VERSION ""

NS_ :

BS_:

BU_: BMS Third_Party_Device

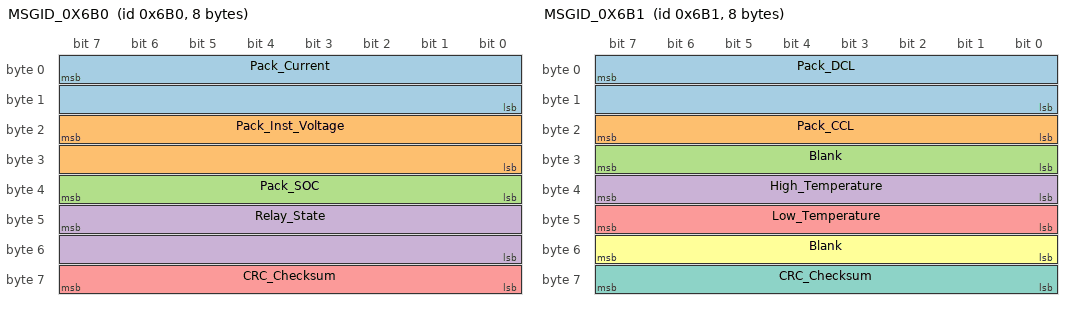
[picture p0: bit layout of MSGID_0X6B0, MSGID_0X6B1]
BO_ 1712 MSGID_0X6B0: 8 BMS
 SG_ Pack_Current : 7|16@0+ (0.1,0) [0|0] "Amps"  Third_Party_Device
 SG_ Pack_Inst_Voltage : 23|16@0+ (0.1,0) [0|0] "Volts"  Third_Party_Device
 SG_ Pack_SOC : 39|8@0+ (0.5,0) [0|0] "Percent"  Third_Party_Device
 SG_ Relay_State : 47|16@0+ (1.0,0) [0|0] ""  Third_Party_Device
 SG_ CRC_Checksum : 63|8@0+ (1.0,1720) [0|0] ""  Third_Party_Device

BO_ 1713 MSGID_0X6B1: 8 BMS
 SG_ Pack_DCL : 7|16@0+ (1.0,0) [0|0] "Amps"  Third_Party_Device
 SG_ Pack_CCL : 23|8@0+ (1.0,0) [0|0] "Amps"  Third_Party_Device
 SG_ Blank : 31|8@0+ (1.0,0) [0|0] ""  Third_Party_Device
 SG_ High_Temperature : 39|8@0+ (1.0,0) [0|0] "Celsius"  Third_Party_Device
 SG_ Low_Temperature : 47|8@0+ (1.0,0) [0|0] "Celsius"  Third_Party_Device
 SG_ Blank : 55|8@0+ (1.0,0) [0|0] ""  Third_Party_Device
 SG_ CRC_Checksum : 63|8@0+ (1.0,1721) [0|0] ""  Third_Party_Device

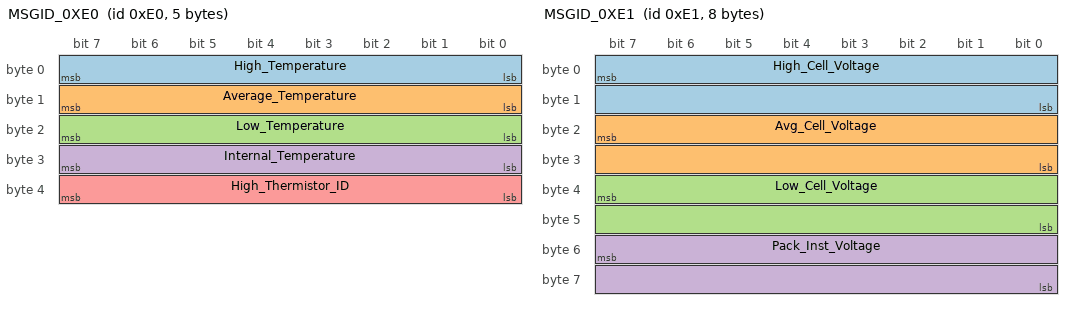
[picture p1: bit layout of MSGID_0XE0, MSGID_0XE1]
BO_ 224 MSGID_0XE0: 5 BMS
 SG_ High_Temperature : 7|8@0+ (1.0,0) [0|0] "Celsius"  Third_Party_Device
 SG_ Average_Temperature : 15|8@0+ (1.0,0) [0|0] "Celsius"  Third_Party_Device
 SG_ Low_Temperature : 23|8@0+ (1.0,0) [0|0] "Celsius"  Third_Party_Device
 SG_ Internal_Temperature : 31|8@0+ (1.0,0) [0|0] "Celsius"  Third_Party_Device
 SG_ High_Thermistor_ID : 39|8@0+ (1.0,0) [0|0] "ID"  Third_Party_Device

BO_ 225 MSGID_0XE1: 8 BMS
 SG_ High_Cell_Voltage : 7|16@0+ (1.0E-4,0) [0|0] "Volts"  Third_Party_Device
 SG_ Avg_Cell_Voltage : 23|16@0+ (1.0E-4,0) [0|0] "Volts"  Third_Party_Device
 SG_ Low_Cell_Voltage : 39|16@0+ (1.0E-4,0) [0|0] "Volts"  Third_Party_Device
 SG_ Pack_Inst_Voltage : 55|16@0+ (0.1,0) [0|0] "Volts"  Third_Party_Device

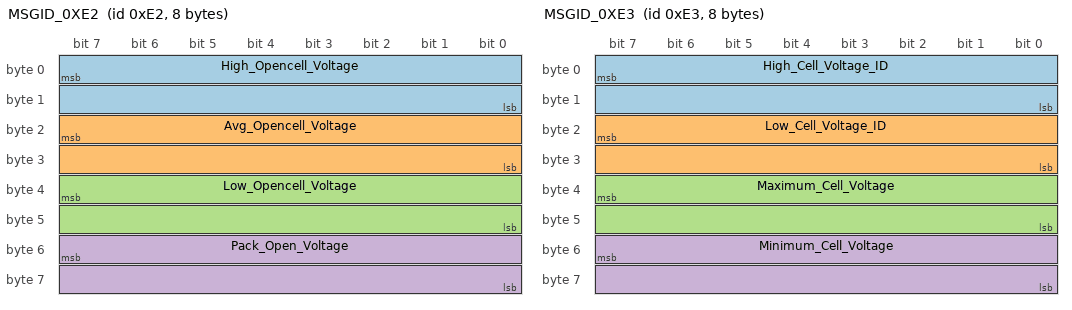
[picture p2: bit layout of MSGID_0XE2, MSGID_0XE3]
BO_ 226 MSGID_0XE2: 8 BMS
 SG_ High_Opencell_Voltage : 7|16@0+ (1.0E-4,0) [0|0] "Volts"  Third_Party_Device
 SG_ Avg_Opencell_Voltage : 23|16@0+ (1.0E-4,0) [0|0] "Volts"  Third_Party_Device
 SG_ Low_Opencell_Voltage : 39|16@0+ (1.0E-4,0) [0|0] "Volts"  Third_Party_Device
 SG_ Pack_Open_Voltage : 55|16@0+ (0.1,0) [0|0] "Volts"  Third_Party_Device

BO_ 227 MSGID_0XE3: 8 BMS
 SG_ High_Cell_Voltage_ID : 7|16@0+ (1.0,0) [0|0] "ID"  Third_Party_Device
 SG_ Low_Cell_Voltage_ID : 23|16@0+ (1.0,0) [0|0] "ID"  Third_Party_Device
 SG_ Maximum_Cell_Voltage : 39|16@0+ (1.0E-4,0) [0|0] "Volts"  Third_Party_Device
 SG_ Minimum_Cell_Voltage : 55|16@0+ (1.0E-4,0) [0|0] "Volts"  Third_Party_Device

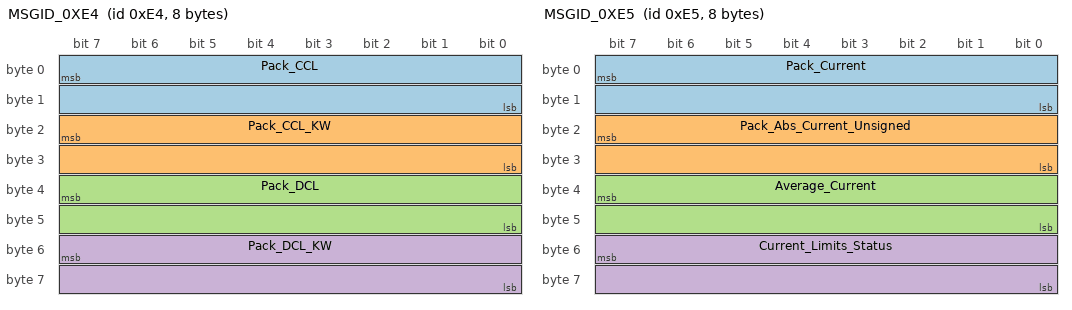
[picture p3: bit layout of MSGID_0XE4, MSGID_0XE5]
BO_ 228 MSGID_0XE4: 8 BMS
 SG_ Pack_CCL : 7|16@0+ (1.0,0) [0|0] "Amps"  Third_Party_Device
 SG_ Pack_CCL_KW : 23|16@0+ (0.1,0) [0|0] "kW"  Third_Party_Device
 SG_ Pack_DCL : 39|16@0+ (1.0,0) [0|0] "Amps"  Third_Party_Device
 SG_ Pack_DCL_KW : 55|16@0+ (0.1,0) [0|0] "kW"  Third_Party_Device

BO_ 229 MSGID_0XE5: 8 BMS
 SG_ Pack_Current : 7|16@0+ (0.1,0) [0|0] "Amps"  Third_Party_Device
 SG_ Pack_Abs_Current_Unsigned : 23|16@0+ (0.1,0) [0|0] "Amps"  Third_Party_Device
 SG_ Average_Current : 39|16@0+ (0.1,0) [0|0] "Amps"  Third_Party_Device
 SG_ Current_Limits_Status : 55|16@0+ (1.0,0) [0|0] ""  Third_Party_Device

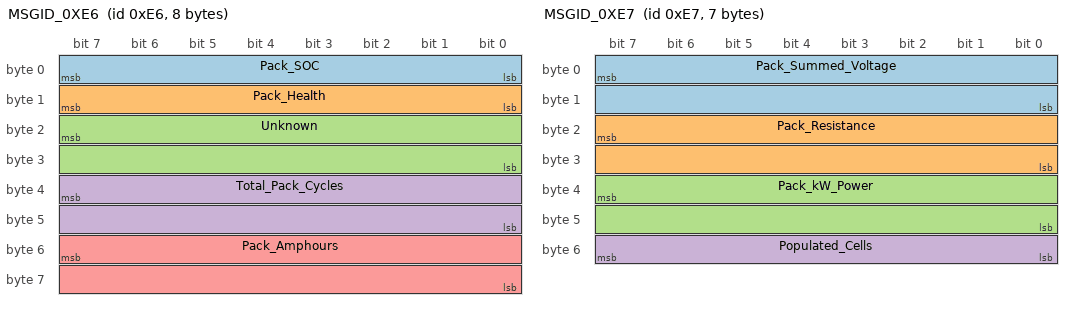
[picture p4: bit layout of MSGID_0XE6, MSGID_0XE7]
BO_ 230 MSGID_0XE6: 8 BMS
 SG_ Pack_SOC : 7|8@0+ (0.5,0) [0|0] "Percent"  Third_Party_Device
 SG_ Pack_Health : 15|8@0+ (1.0,0) [0|0] "Percent"  Third_Party_Device
 SG_ Unknown : 23|16@0+ (1.0,0) [0|0] ""  Third_Party_Device
 SG_ Total_Pack_Cycles : 39|16@0+ (1.0,0) [0|0] "Num"  Third_Party_Device
 SG_ Pack_Amphours : 55|16@0+ (0.1,0) [0|0] "Amphours"  Third_Party_Device

BO_ 231 MSGID_0XE7: 7 BMS
 SG_ Pack_Summed_Voltage : 7|16@0+ (0.01,0) [0|0] "Volts"  Third_Party_Device
 SG_ Pack_Resistance : 23|16@0+ (0.001,0) [0|0] "Ohms"  Third_Party_Device
 SG_ Pack_kW_Power : 39|16@0+ (0.1,0) [0|0] "kW"  Third_Party_Device
 SG_ Populated_Cells : 55|8@0+ (1.0,0) [0|0] "Num"  Third_Party_Device

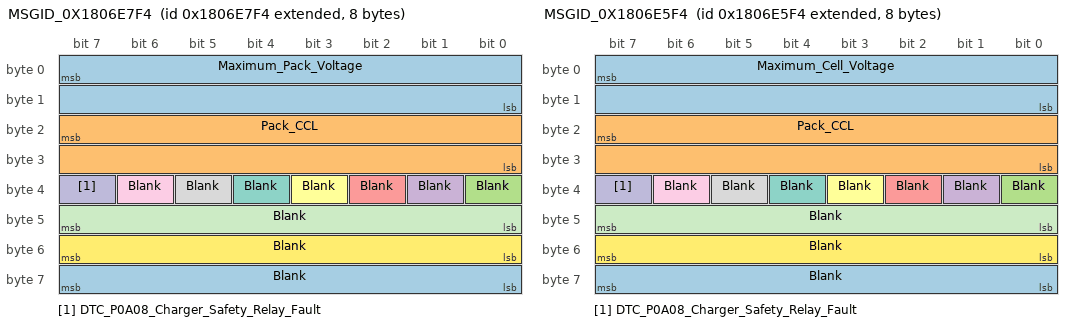
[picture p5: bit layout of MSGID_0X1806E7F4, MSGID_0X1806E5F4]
BO_ 2550589428 MSGID_0X1806E7F4: 8 BMS
 SG_ Maximum_Pack_Voltage : 7|16@0+ (0.1,0) [0|0] "Volts"  Third_Party_Device
 SG_ Pack_CCL : 23|16@0+ (0.1,0) [0|0] "Amps"  Third_Party_Device
 SG_ Blank : 32|1@1+ (1.0,0) [0|1] ""  Third_Party_Device
 SG_ Blank : 33|1@1+ (1.0,0) [0|1] ""  Third_Party_Device
 SG_ Blank : 34|1@1+ (1.0,0) [0|1] ""  Third_Party_Device
 SG_ Blank : 35|1@1+ (1.0,0) [0|1] ""  Third_Party_Device
 SG_ Blank : 36|1@1+ (1.0,0) [0|1] ""  Third_Party_Device
 SG_ Blank : 37|1@1+ (1.0,0) [0|1] ""  Third_Party_Device
 SG_ Blank : 38|1@1+ (1.0,0) [0|1] ""  Third_Party_Device
 SG_ DTC_P0A08_Charger_Safety_Relay_Fault : 39|1@1+ (1.0,0) [0|1] ""  Third_Party_Device
 SG_ Blank : 47|8@0+ (0.1,0) [0|0] ""  Third_Party_Device
 SG_ Blank : 55|8@0+ (1.0,0) [0|0] ""  Third_Party_Device
 SG_ Blank : 63|8@0+ (1.0,0) [0|0] ""  Third_Party_Device

BO_ 2550588916 MSGID_0X1806E5F4: 8 BMS
 SG_ Maximum_Cell_Voltage : 7|16@0+ (7.142857142857144E-4,0) [0|0] "Volts"  Third_Party_Device
 SG_ Pack_CCL : 23|16@0+ (0.1,0) [0|0] "Amps"  Third_Party_Device
 SG_ Blank : 32|1@1+ (1.0,0) [0|1] ""  Third_Party_Device
 SG_ Blank : 33|1@1+ (1.0,0) [0|1] ""  Third_Party_Device
 SG_ Blank : 34|1@1+ (1.0,0) [0|1] ""  Third_Party_Device
 SG_ Blank : 35|1@1+ (1.0,0) [0|1] ""  Third_Party_Device
 SG_ Blank : 36|1@1+ (1.0,0) [0|1] ""  Third_Party_Device
 SG_ Blank : 37|1@1+ (1.0,0) [0|1] ""  Third_Party_Device
 SG_ Blank : 38|1@1+ (1.0,0) [0|1] ""  Third_Party_Device
 SG_ DTC_P0A08_Charger_Safety_Relay_Fault : 39|1@1+ (1.0,0) [0|1] ""  Third_Party_Device
 SG_ Blank : 47|8@0+ (0.1,0) [0|0] ""  Third_Party_Device
 SG_ Blank : 55|8@0+ (1.0,0) [0|0] ""  Third_Party_Device
 SG_ Blank : 63|8@0+ (1.0,0) [0|0] ""  Third_Party_Device

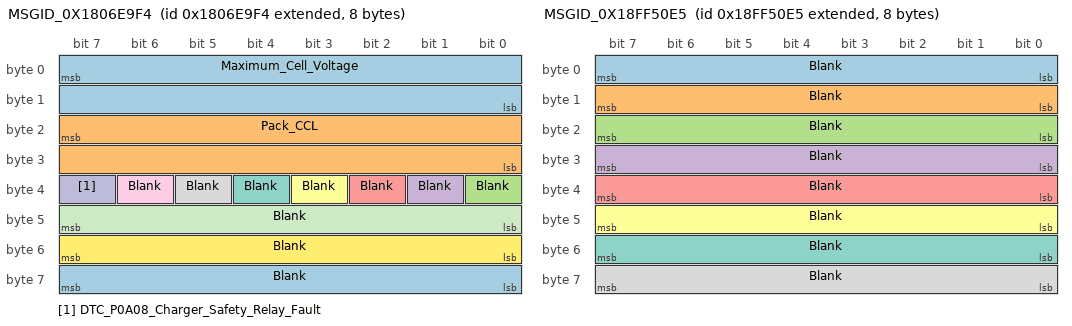
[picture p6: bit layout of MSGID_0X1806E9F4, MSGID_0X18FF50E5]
BO_ 2550589940 MSGID_0X1806E9F4: 8 BMS
 SG_ Maximum_Cell_Voltage : 7|16@0+ (7.142857142857144E-4,0) [0|0] "Volts"  Third_Party_Device
 SG_ Pack_CCL : 23|16@0+ (0.1,0) [0|0] "Amps"  Third_Party_Device
 SG_ Blank : 32|1@1+ (1.0,0) [0|1] ""  Third_Party_Device
 SG_ Blank : 33|1@1+ (1.0,0) [0|1] ""  Third_Party_Device
 SG_ Blank : 34|1@1+ (1.0,0) [0|1] ""  Third_Party_Device
 SG_ Blank : 35|1@1+ (1.0,0) [0|1] ""  Third_Party_Device
 SG_ Blank : 36|1@1+ (1.0,0) [0|1] ""  Third_Party_Device
 SG_ Blank : 37|1@1+ (1.0,0) [0|1] ""  Third_Party_Device
 SG_ Blank : 38|1@1+ (1.0,0) [0|1] ""  Third_Party_Device
 SG_ DTC_P0A08_Charger_Safety_Relay_Fault : 39|1@1+ (1.0,0) [0|1] ""  Third_Party_Device
 SG_ Blank : 47|8@0+ (1.0,0) [0|0] ""  Third_Party_Device
 SG_ Blank : 55|8@0+ (1.0,0) [0|0] ""  Third_Party_Device
 SG_ Blank : 63|8@0+ (1.0,0) [0|0] ""  Third_Party_Device

BO_ 2566869221 MSGID_0X18FF50E5: 8 Third_Party_Device
 SG_ Blank : 7|8@0+ (1.0,0) [0|0] ""  BMS
 SG_ Blank : 15|8@0+ (1.0,0) [0|0] ""  BMS
 SG_ Blank : 23|8@0+ (1.0,0) [0|0] ""  BMS
 SG_ Blank : 31|8@0+ (1.0,0) [0|0] ""  BMS
 SG_ Blank : 39|8@0+ (1.0,0) [0|0] ""  BMS
 SG_ Blank : 47|8@0+ (1.0,0) [0|0] ""  BMS
 SG_ Blank : 55|8@0+ (1.0,0) [0|0] ""  BMS
 SG_ Blank : 63|8@0+ (1.0,0) [0|0] ""  BMS

CM_ BO_ 1712 "This ID Transmits at 8 ms.";
CM_ BO_ 1713 "This ID Transmits at 104 ms.";
CM_ BO_ 224 "This ID Transmits at 8 ms.";
CM_ BO_ 225 "This ID Transmits at 8 ms.";
CM_ BO_ 226 "This ID Transmits at 8 ms.";
CM_ BO_ 227 "This ID Transmits at 8 ms.";
CM_ BO_ 228 "This ID Transmits at 2000 ms.";
CM_ BO_ 229 "This ID Transmits at 8 ms.";
CM_ BO_ 230 "This ID Transmits at 8 ms.";
CM_ BO_ 231 "This ID Transmits at 8 ms.";
CM_ BO_ 2550589428 "This ID Transmits at 808 ms.";
CM_ BO_ 2550588916 "This ID Transmits at 808 ms.";
CM_ BO_ 2550589940 "This ID Transmits at 808 ms.";
